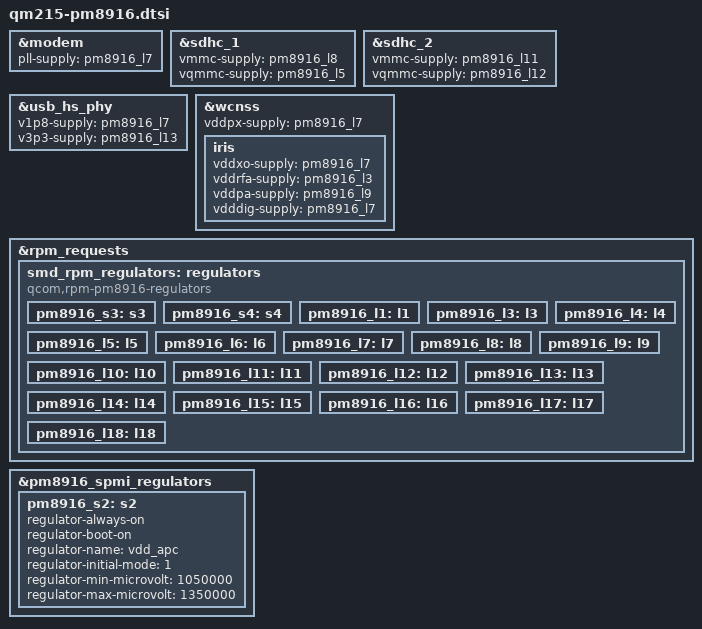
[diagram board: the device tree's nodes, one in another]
// SPDX-License-Identifier: GPL-2.0-only

#include "qm215.dtsi"
#include "pm8916.dtsi"

/*
&cpr {
	status = "okay";
	vdd-apc-supply = <&pm8916_s2>;
};
*/

&modem {
	pll-supply = <&pm8916_l7>;
};

&sdhc_1 {
	vmmc-supply = <&pm8916_l8>;
	vqmmc-supply = <&pm8916_l5>;
};

&sdhc_2 {
	vmmc-supply = <&pm8916_l11>;
	vqmmc-supply = <&pm8916_l12>;
};

&usb_hs_phy {
	v1p8-supply = <&pm8916_l7>;
	v3p3-supply = <&pm8916_l13>;
};

&wcnss {
	vddpx-supply = <&pm8916_l7>;

	iris {
		vddxo-supply = <&pm8916_l7>;
		vddrfa-supply = <&pm8916_l3>;
		vddpa-supply = <&pm8916_l9>;
		vdddig-supply = <&pm8916_l7>;
	};
};

&rpm_requests {
	smd_rpm_regulators: regulators {
		compatible = "qcom,rpm-pm8916-regulators";

		/* pm8916_s1 is managed by rpmpd (QM215_VDDCX) */
		pm8916_s3: s3 {};
		pm8916_s4: s4 {};

		pm8916_l1: l1 {};
		/* pm8916_l2 is managed by rpmpd (QM215_VDDMX) */
		pm8916_l3: l3 {};
		pm8916_l4: l4 {};
		pm8916_l5: l5 {};
		pm8916_l6: l6 {};
		pm8916_l7: l7 {};
		pm8916_l8: l8 {};
		pm8916_l9: l9 {};
		pm8916_l10: l10 {};
		pm8916_l11: l11 {};
		pm8916_l12: l12 {};
		pm8916_l13: l13 {};
		pm8916_l14: l14 {};
		pm8916_l15: l15 {};
		pm8916_l16: l16 {};
		pm8916_l17: l17 {};
		pm8916_l18: l18 {};
	};
};

&pm8916_spmi_regulators {
	pm8916_s2: s2 {
		regulator-always-on;
		regulator-boot-on;
		regulator-name = "vdd_apc";
		regulator-initial-mode = <1>;
		regulator-min-microvolt = <1050000>;
		regulator-max-microvolt = <1350000>;
	};
};
